# GD32H71x_72x register map
File version: 1.0
CPU: CM7 r1p2, little endian, MPU, FPU, 4 interrupt priority bits
Registers are 32-bit, read-write, reset 0x0 unless marked. A register's access mark holds for its fields unless they carry their own. Offsets are from the block's base; [hi:lo] are bit positions.

## CMP — Comparator
Base 0x58003800
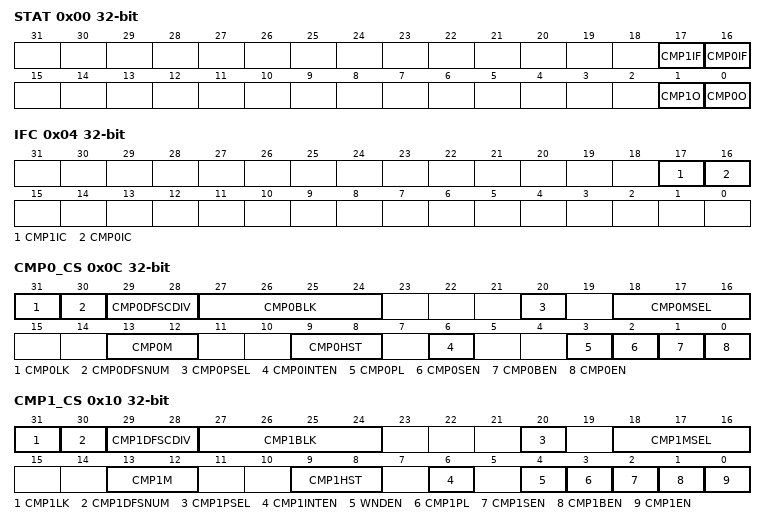
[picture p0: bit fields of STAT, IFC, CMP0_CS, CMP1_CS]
0x00 STAT ro — CMP status register
  [17] CMP1IF — CMP1 interrupt flag
  [16] CMP0IF — CMP0 interrupt flag
  [1] CMP1O — CMP1 output state
  [0] CMP0O — CMP0 output state
0x04 IFC wo — CMP interrupt flag clear register
  [17] CMP1IC — CMP1 interrupt flag clear
  [16] CMP0IC — CMP0 interrupt flag clear
0x08 SR — CMP alternate select register
  [10:0] AFSE — CMP selects alternate output ports
0x0C CMP0_CS — CMP0 control/status register
  [31] CMP0LK — CMP0 lock
  [30] CMP0DFSNUM — CMP0 digital filter sampling number
  [29:28] CMP0DFSCDIV — CMP0 digital filter sampling clock division
  [27:24] CMP0BLK — CMP0 output blanking source
  [20] CMP0PSEL — CMP0_IP input selection
  [18:16] CMP0MSEL — CMP0_IM internal input selection
  [13:12] CMP0M — CMP0 mode
  [9:8] CMP0HST — CMP0 hysteresis
  [6] CMP0INTEN — CMP0 interrupt enable
  [3] CMP0PL — Polarity of CMP0 output
  [2] CMP0SEN — Voltage scaler enable bit
  [1] CMP0BEN — Scaler bridge enable bit
  [0] CMP0EN — CMP0 enable
0x10 CMP1_CS — CMP1 control/status register
  [31] CMP1LK — CMP1 lock
  [30] CMP1DFSNUM — CMP1 digital filter sampling number
  [29:28] CMP1DFSCDIV — CMP1 digital filter sampling clock division
  [27:24] CMP1BLK — CMP1 output blanking source
  [20] CMP1PSEL — CMP1_IP input selection
  [18:16] CMP1MSEL — CMP1_IM internal input selection
  [13:12] CMP1M — CMP1 mode
  [9:8] CMP1HST — CMP1 hysteresis
  [6] CMP1INTEN — CMP1 interrupt enable
  [4] WNDEN — Window mode enable
  [3] CMP1PL — Polarity of CMP1 output
  [2] CMP1SEN — Voltage scaler enable bit
  [1] CMP1BEN — Scaler bridge enable bit
  [0] CMP1EN — CMP1 enable

## CPDM_OSPI — OSPI clock phase delay module
Base 0x52006000
Same registers: CPDM_SDIO1 0x48022800, CPDM_SDIO0 0x52008000
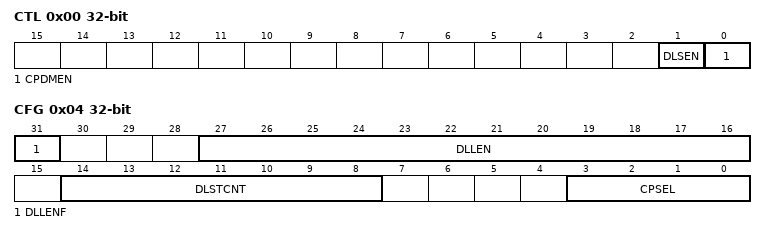
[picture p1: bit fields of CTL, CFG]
0x00 CTL — Control register
  [1] DLSEN — CPDM delay line sample module enable bit
  [0] CPDMEN — CPDM enable bit
0x04 CFG access per field — Configuration register
  [31] DLLENF ro — Valid mark of delay line length
  [27:16] DLLEN ro — Delay line length
  [14:8] DLSTCNT rw — Defines a delay step count for a unit delay UNIT
  [3:0] CPSEL rw — Select the phase of the output clock

## CRC — Cyclic redundancy checks management unit
Base 0x58024C00
0x00 DATA reset 0xFFFFFFFF
  [31:0] DATA — CRC calculation result bits
0x04 FDATA — Free data register
  [7:0] FDATA — Free data register bits
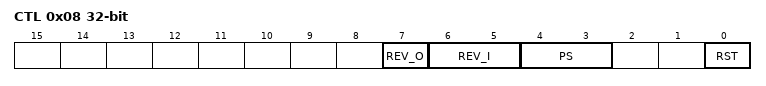
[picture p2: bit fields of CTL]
0x08 CTL — Control register
  [7] REV_O — Reverse output data value in bit order
  [6:5] REV_I — Reverse type for input data
  [4:3] PS — Size of polynomial
  [0] RST — Software writes and reads.
0x10 IDATA reset 0xFFFFFFFF — Initialization data register
  [31:0] IDATA — Configurable initial CRC data value
0x14 POLY reset 0x4C11DB7 — Polynomial register
  [31:0] POLY — User configurable polynomial value

## CTC0 — Clock trim controller0
Base 0x40008400
Same registers: CTC1 0x40008800
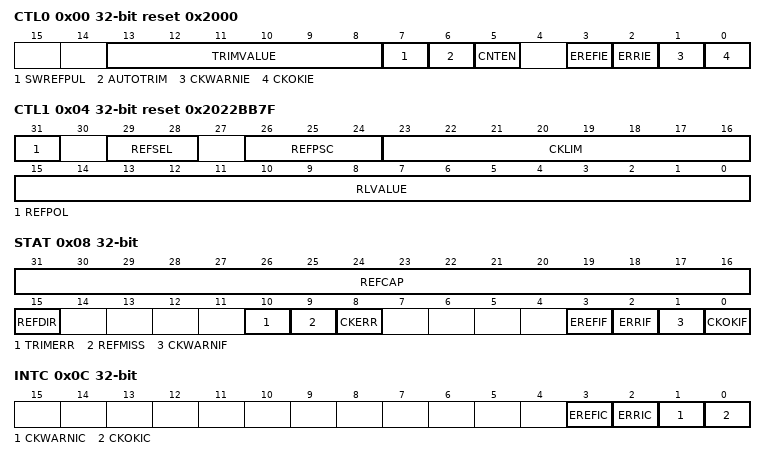
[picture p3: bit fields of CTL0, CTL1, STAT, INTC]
0x00 CTL0 access per field reset 0x2000 — Control register 0
  [13:8] TRIMVALUE rw — IRC48M / IRC64M trim value
  [7] SWREFPUL wo — Software reference source sync pulse
  [6] AUTOTRIM rw — Hardware automatically trim mode
  [5] CNTEN rw — CTC counter enable
  [3] EREFIE rw — EREFIF interrupt enable
  [2] ERRIE rw — Error (ERRIF) interrupt enable
  [1] CKWARNIE rw — Clock trim warning (CKWARNIF) interrupt enable
  [0] CKOKIE rw — Clock trim OK (CKOKIF) interrupt enable
0x04 CTL1 reset 0x2022BB7F — Control register 1
  [31] REFPOL — Reference signal source polarity
  [29:28] REFSEL — Reference signal source selection
  [26:24] REFPSC — Reference signal source prescaler
  [23:16] CKLIM — Clock trim base limit value
  [15:0] RLVALUE — CTC counter reload value
0x08 STAT ro — Status register
  [31:16] REFCAP — CTC counter capture when reference sync pulse.
  [15] REFDIR — CTC trim counter direction when reference sync pulse
  [10] TRIMERR — Trim value error bit
  [9] REFMISS — Reference sync pulse miss
  [8] CKERR — Clock trim error bit
  [3] EREFIF — Expect reference interrupt flag
  [2] ERRIF — Error interrupt flag
  [1] CKWARNIF — Clock trim warning interrupt flag
  [0] CKOKIF — Clock trim OK interrupt flag
0x0C INTC wo — Interrupt clear register
  [3] EREFIC — EREFIF interrupt clear bit
  [2] ERRIC — ERRIF interrupt clear bit
  [1] CKWARNIC — CKWARNIF interrupt clear bit
  [0] CKOKIC — CKOKIF interrupt clear bit
